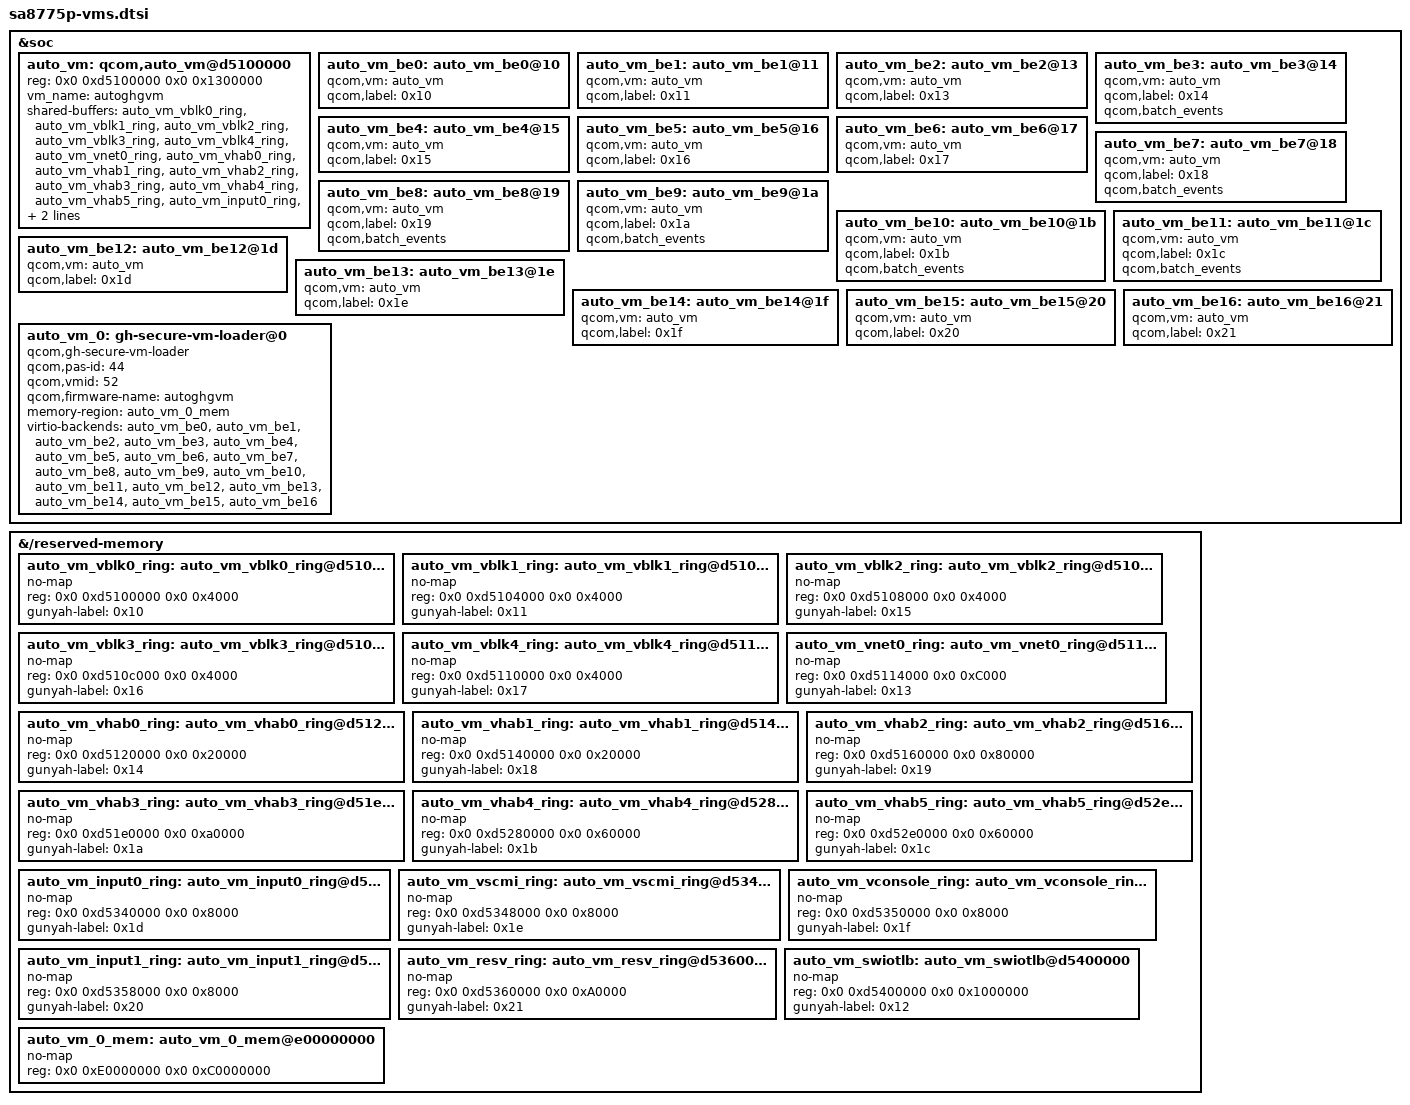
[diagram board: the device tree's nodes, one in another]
// SPDX-License-Identifier: GPL-2.0-only
/*
* Copyright (c) 2023 Qualcomm Innovation Center, Inc. All rights reserved.
*/

&soc {
	auto_vm: qcom,auto_vm@d5100000 {
		reg = <0x0 0xd5100000 0x0 0x1300000>;
		vm_name = "autoghgvm";
		shared-buffers = <&auto_vm_vblk0_ring &auto_vm_vblk1_ring &auto_vm_vblk2_ring &auto_vm_vblk3_ring &auto_vm_vblk4_ring &auto_vm_vnet0_ring &auto_vm_vhab0_ring &auto_vm_vhab1_ring &auto_vm_vhab2_ring &auto_vm_vhab3_ring &auto_vm_vhab4_ring &auto_vm_vhab5_ring &auto_vm_input0_ring &auto_vm_vscmi_ring &auto_vm_resv_ring &auto_vm_swiotlb>;
	};

	auto_vm_be0: auto_vm_be0@10 {
		qcom,vm = <&auto_vm>;
		qcom,label = <0x10>;
	};

	auto_vm_be1: auto_vm_be1@11 {
		qcom,vm = <&auto_vm>;
		qcom,label = <0x11>;
	};

	auto_vm_be2: auto_vm_be2@13 {
		qcom,vm = <&auto_vm>;
		qcom,label = <0x13>;
	};

	auto_vm_be3: auto_vm_be3@14 {
		qcom,vm = <&auto_vm>;
		qcom,label = <0x14>;
		qcom,batch_events;
	};

	auto_vm_be4: auto_vm_be4@15 {
		qcom,vm = <&auto_vm>;
		qcom,label = <0x15>;
	};

	auto_vm_be5: auto_vm_be5@16 {
		qcom,vm = <&auto_vm>;
		qcom,label = <0x16>;
	};

	auto_vm_be6: auto_vm_be6@17 {
		qcom,vm = <&auto_vm>;
		qcom,label = <0x17>;
	};

	auto_vm_be7: auto_vm_be7@18 {
		qcom,vm = <&auto_vm>;
		qcom,label = <0x18>;
		qcom,batch_events;
	};

	auto_vm_be8: auto_vm_be8@19 {
		qcom,vm = <&auto_vm>;
		qcom,label = <0x19>;
		qcom,batch_events;
	};

	auto_vm_be9: auto_vm_be9@1a {
		qcom,vm = <&auto_vm>;
		qcom,label = <0x1a>;
		qcom,batch_events;
	};

	auto_vm_be10: auto_vm_be10@1b {
		qcom,vm = <&auto_vm>;
		qcom,label = <0x1b>;
		qcom,batch_events;
	};

	auto_vm_be11: auto_vm_be11@1c {
		qcom,vm = <&auto_vm>;
		qcom,label = <0x1c>;
		qcom,batch_events;
	};

	auto_vm_be12: auto_vm_be12@1d {
		qcom,vm = <&auto_vm>;
		qcom,label = <0x1d>;
	};

	auto_vm_be13: auto_vm_be13@1e {
		qcom,vm = <&auto_vm>;
		qcom,label = <0x1e>;
	};

	auto_vm_be14: auto_vm_be14@1f {
		qcom,vm = <&auto_vm>;
		qcom,label = <0x1f>;
	};

	auto_vm_be15: auto_vm_be15@20 {
		qcom,vm = <&auto_vm>;
		qcom,label = <0x20>;
	};

	auto_vm_be16: auto_vm_be16@21 {
		qcom,vm = <&auto_vm>;
		qcom,label = <0x21>;
	};

	auto_vm_0: gh-secure-vm-loader@0 {
		compatible = "qcom,gh-secure-vm-loader";
		qcom,pas-id = <44>;
		qcom,vmid = <52>;
		qcom,firmware-name = "autoghgvm";
		memory-region = <&auto_vm_0_mem>;
		virtio-backends = <&auto_vm_be0 &auto_vm_be1 &auto_vm_be2 &auto_vm_be3 &auto_vm_be4 &auto_vm_be5 &auto_vm_be6 &auto_vm_be7 &auto_vm_be8 &auto_vm_be9 &auto_vm_be10 &auto_vm_be11 &auto_vm_be12 &auto_vm_be13 &auto_vm_be14 &auto_vm_be15 &auto_vm_be16>;
	};
};

&{/reserved-memory} {
	#address-cells = <2>;
	#size-cells = <2>;
	ranges;

	auto_vm_vblk0_ring: auto_vm_vblk0_ring@d5100000 {
		no-map;
		reg = <0x0 0xd5100000 0x0 0x4000>;
		gunyah-label = <0x10>;
	};

	auto_vm_vblk1_ring: auto_vm_vblk1_ring@d5104000 {
		no-map;
		reg = <0x0 0xd5104000 0x0 0x4000>;
		gunyah-label = <0x11>;
	};

	auto_vm_vblk2_ring: auto_vm_vblk2_ring@d5108000 {
		no-map;
		reg = <0x0 0xd5108000 0x0 0x4000>;
		gunyah-label = <0x15>;
	};

	auto_vm_vblk3_ring: auto_vm_vblk3_ring@d510c000 {
		no-map;
		reg = <0x0 0xd510c000 0x0 0x4000>;
		gunyah-label = <0x16>;
	};

	auto_vm_vblk4_ring: auto_vm_vblk4_ring@d5110000 {
		no-map;
		reg = <0x0 0xd5110000 0x0 0x4000>;
		gunyah-label = <0x17>;
	};

	auto_vm_vnet0_ring: auto_vm_vnet0_ring@d5114000 {
		no-map;
		reg = <0x0 0xd5114000 0x0 0xC000>;
		gunyah-label = <0x13>;
	};

	auto_vm_vhab0_ring: auto_vm_vhab0_ring@d5120000 {
		no-map;
		reg = <0x0 0xd5120000 0x0 0x20000>;
		gunyah-label = <0x14>;
	};

	auto_vm_vhab1_ring: auto_vm_vhab1_ring@d5140000 {
		no-map;
		reg = <0x0 0xd5140000 0x0 0x20000>;
		gunyah-label = <0x18>;
	};

	auto_vm_vhab2_ring: auto_vm_vhab2_ring@d5160000 {
		no-map;
		reg = <0x0 0xd5160000 0x0 0x80000>;
		gunyah-label = <0x19>;
	};

	auto_vm_vhab3_ring: auto_vm_vhab3_ring@d51e0000 {
		no-map;
		reg = <0x0 0xd51e0000 0x0 0xa0000>;
		gunyah-label = <0x1a>;
	};

	auto_vm_vhab4_ring: auto_vm_vhab4_ring@d5280000 {
		no-map;
		reg = <0x0 0xd5280000 0x0 0x60000>;
		gunyah-label = <0x1b>;
	};

	auto_vm_vhab5_ring: auto_vm_vhab5_ring@d52e0000 {
		no-map;
		reg = <0x0 0xd52e0000 0x0 0x60000>;
		gunyah-label = <0x1c>;
	};

	auto_vm_input0_ring: auto_vm_input0_ring@d5340000 {
		no-map;
		reg = <0x0 0xd5340000 0x0 0x8000>;
		gunyah-label = <0x1d>;
	};

	auto_vm_vscmi_ring: auto_vm_vscmi_ring@d5348000 {
		no-map;
		reg = <0x0 0xd5348000 0x0 0x8000>;
		gunyah-label = <0x1e>;
	};

	auto_vm_vconsole_ring: auto_vm_vconsole_ring@d5350000 {
		no-map;
		reg = <0x0 0xd5350000 0x0 0x8000>;
		gunyah-label = <0x1f>;
	};

	auto_vm_input1_ring: auto_vm_input1_ring@d5358000 {
		no-map;
		reg = <0x0 0xd5358000 0x0 0x8000>;
		gunyah-label = <0x20>;
	};

	auto_vm_resv_ring: auto_vm_resv_ring@d5360000 {
		no-map;
		reg = <0x0 0xd5360000 0x0 0xA0000>;
		gunyah-label = <0x21>;
	};

	auto_vm_swiotlb: auto_vm_swiotlb@d5400000 {
		no-map;
		reg = <0x0 0xd5400000 0x0 0x1000000>;
		gunyah-label = <0x12>;
	};

	auto_vm_0_mem: auto_vm_0_mem@e00000000 {
		no-map;
		reg = <0x0 0xE0000000 0x0 0xC0000000>;
	};
};
